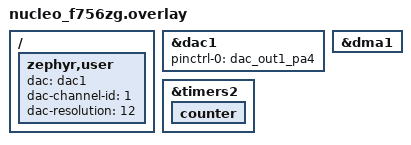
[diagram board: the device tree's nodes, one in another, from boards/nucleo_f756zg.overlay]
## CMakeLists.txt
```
# SPDX-License-Identifier: Apache-2.0

cmake_minimum_required(VERSION 3.20.0)

find_package(Zephyr REQUIRED HINTS $ENV{ZEPHYR_BASE})
project(DAC)

target_sources(app PRIVATE src/main.c)
target_sources(app PRIVATE src/dac.c)
```

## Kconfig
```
mainmenu "DAC_APP"

source "Kconfig.zephyr"
config DAC_APP_STM32
  default y
  bool
  select USE_STM32_HAL_DAC
  select USE_STM32_HAL_DAC_EX
  select USE_STM32_HAL_DMA
  select USE_STM32_HAL_CORTEX
  select USE_STM32_HAL_TIM
  select USE_STM32_HAL_TIM_EX
```

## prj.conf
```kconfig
CONFIG_DAC=y

CONFIG_SHELL=y
CONFIG_DAC_SHELL=y

CONFIG_USE_STM32_ASSERT=y

CONFIG_DMA=y
```

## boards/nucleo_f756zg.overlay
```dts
/ {
	zephyr,user {
		dac = <&dac1>;
		dac-channel-id = <1>;
		dac-resolution = <12>;
	};
};

&dac1 {
		status = "okay";
		pinctrl-0 = <&dac_out1_pa4>;
		pinctrl-names = "default";
};


//dma1: dma@40026000 {
//compatible = "st,stm32-dma-v1";
&dma1 {
		status = "okay";

};

&timers2 {
		status = "okay";
		counter {
			status = "okay";
		};

};
```

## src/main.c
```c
/*
 * Copyright (c) 2020 Libre Solar Technologies GmbH
 *
 * SPDX-License-Identifier: Apache-2.0
 */

#include <zephyr/kernel.h>
#include <zephyr/sys/printk.h>
#include <zephyr/drivers/dac.h>
#include "stm32f7xx_hal.h"
#include "stm32f7xx_ll_dac.h"
#include "stm32f7xx_hal_dac.h"
#include "dac.h"

#define ZEPHYR_USER_NODE DT_PATH(zephyr_user)

#if (DT_NODE_HAS_PROP(ZEPHYR_USER_NODE, dac) && \
	DT_NODE_HAS_PROP(ZEPHYR_USER_NODE, dac_channel_id) && \
	DT_NODE_HAS_PROP(ZEPHYR_USER_NODE, dac_resolution))
#define DAC_NODE DT_PHANDLE(ZEPHYR_USER_NODE, dac)
#define DAC_CHANNEL_ID DT_PROP(ZEPHYR_USER_NODE, dac_channel_id)
#define DAC_RESOLUTION DT_PROP(ZEPHYR_USER_NODE, dac_resolution)
#else
#error "Unsupported board: see README and check /zephyr,user node"
#define DAC_NODE DT_INVALID_NODE
#define DAC_CHANNEL_ID 0
#define DAC_RESOLUTION 0
#endif

static const struct device *const dac_dev = DEVICE_DT_GET(DAC_NODE);

static const struct dac_channel_cfg dac_ch_cfg = {
	.channel_id  = DAC_CHANNEL_ID,
	.resolution  = DAC_RESOLUTION,
	.buffered = true
};

int main(void)
{
	if (!device_is_ready(dac_dev)) {
		printk("DAC device %s is not ready\n", dac_dev->name);
		return 0;
	}

	int ret = dac_channel_setup(dac_dev, &dac_ch_cfg);

	if (ret != 0) {
		printk("Setting up of DAC channel failed with code %d\n", ret);
		return 0;
	}

	printk("Generating sawtooth signal at DAC channel %d.\n",
		DAC_CHANNEL_ID);
	//int dac_dev = 0;
	//ret = dac_write_value(dac_dev, DAC_CHANNEL_ID, 0);
	//k_timer_init(&timer2);
	//k_timer_start(&timer2, K_NO_WAIT, K_MSEC(1));
	ret = init_dac();
	ret = run_dac();
}
```

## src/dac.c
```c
#include <zephyr/kernel.h>
#include <zephyr/sys/printk.h>
//#include <zephyr/drivers/dac.h>
//#include "stm32f7xx_hal.h"
#include "stm32f7xx_ll_dac.h" // Also called in driver
#include "stm32f7xx_hal_dac.h"
#include "stm32f7xx_hal_cortex.h" // for HAL_NVIC EnableIRQ and HAL_NVIC SetPriority

DAC_HandleTypeDef hdac1;
DMA_HandleTypeDef hdma_dac1;
TIM_HandleTypeDef htim2;

void Error_Handler(void);
static void MX_DAC1_Init(void);
static void MX_DMA_Init(void);
static void MX_TIM2_Init(void);

#define NS  128

int init_dac(void)
{

	uint32_t DAC_OUT[4] = {0, 1241, 2482, 3723};
	uint32_t Wave_LUT[NS] = {
		2048, 2149, 2250, 2350, 2450, 2549, 2646, 2742, 2837, 2929, 3020, 3108, 3193, 3275, 3355,
		3431, 3504, 3574, 3639, 3701, 3759, 3812, 3861, 3906, 3946, 3982, 4013, 4039, 4060, 4076,
		4087, 4094, 4095, 4091, 4082, 4069, 4050, 4026, 3998, 3965, 3927, 3884, 3837, 3786, 3730,
		3671, 3607, 3539, 3468, 3394, 3316, 3235, 3151, 3064, 2975, 2883, 2790, 2695, 2598, 2500,
		2400, 2300, 2199, 2098, 1997, 1896, 1795, 1695, 1595, 1497, 1400, 1305, 1212, 1120, 1031,
		944, 860, 779, 701, 627, 556, 488, 424, 365, 309, 258, 211, 168, 130, 97,
		69, 45, 26, 13, 4, 0, 1, 8, 19, 35, 56, 82, 113, 149, 189,
		234, 283, 336, 394, 456, 521, 591, 664, 740, 820, 902, 987, 1075, 1166, 1258,
		1353, 1449, 1546, 1645, 1745, 1845, 1946, 2047
	};
	uint8_t i = 0;
	uint32_t err = 0;

//	HAL_Init();
//	SystemClock_Config();
//	MX_GPIO_Init();
	MX_DAC1_Init();
	MX_DMA_Init();
	MX_TIM2_Init();
//	DAC1, channel 1 (PA4) is initialized via Zephyr API
	/* Clocks, pinctrl, channel count and resolution
	 * handled by Zephyr driver in drivers/dac/dac_stm32.c
	 * */


	err = HAL_DAC_Start_DMA(&hdac1, DAC_CHANNEL_1, (uint32_t*)Wave_LUT, 128, DAC_ALIGN_12B_R);
	if (err != HAL_OK) {
		printk(err);
	 }
	HAL_TIM_Base_Start(&htim2);

	printk("IRQ 0x%x\n", arch_irq_is_enabled(16));
	printk("IRQ 0x%x\n", arch_irq_is_enabled(15));

/*	k_msleep(50);
	while (1)
	{
		DAC1->DHR12R1 = DAC_OUT[i++];
		if(i == 4)
			i = 0;
		//HAL_Delay(50); // STM32 50ms systick delay
		k_msleep(50);
	}*/
/*	while(1)
	{
		err = HAL_DAC_SetValue(&hdac1, DAC_CHANNEL_1, DAC_ALIGN_12B_R, Wave_LUT);
		k_msleep(1);
	}*/
		return 0;
}

void HAL_DAC_ConvHalfCpltCallbackCh1(DAC_HandleTypeDef *hdac)
{
	printk("Yo!");
}
void SystemClock_Config(void)
{
/*
dac1: dac@40007400 {
	compatible = "st,stm32-dac";
	reg = <0x40007400 0x400>;
	clocks = <&rcc STM32_CLOCK_BUS_APB1 0x20000000>;
	status = "disabled";
	#io-channel-cells = <1>;
};
*/
/*
rcc: rcc@40023800 {
	compatible = "st,stm32-rcc";
	#clock-cells = <2>;
	reg = <0x40023800 0x400>;
*/
}

static void MX_DAC1_Init(void)
{
	DAC_ChannelConfTypeDef sConfig = {0};

    /* Peripheral clock enable */
    __HAL_RCC_DAC_CLK_ENABLE();
/** DAC Initialization
 * Already done?
*/
	hdac1.Instance = DAC1;
	if (HAL_DAC_Init(&hdac1) != HAL_OK)
	{
	      Error_Handler();
	}
	/** DAC channel OUT1 config
	*/

	//sConfig.DAC_Trigger = DAC_TRIGGER_NONE;
	sConfig.DAC_Trigger = DAC_TRIGGER_T2_TRGO;
	sConfig.DAC_OutputBuffer = DAC_OUTPUTBUFFER_ENABLE;
	if (HAL_DAC_ConfigChannel(&hdac1, &sConfig, DAC_CHANNEL_1) != HAL_OK)
	{
	      Error_Handler();
	}
	/* Enable DMA */
	/* DAC DMA Init */
	/* DAC1 Init */
	hdma_dac1.Instance = DMA1_Stream5;
	hdma_dac1.Init.Channel = DMA_CHANNEL_7;
	hdma_dac1.Init.Direction = DMA_MEMORY_TO_PERIPH;
	hdma_dac1.Init.PeriphInc = DMA_PINC_DISABLE;
	hdma_dac1.Init.MemInc = DMA_MINC_ENABLE;
    hdma_dac1.Init.PeriphDataAlignment = DMA_PDATAALIGN_WORD;
    hdma_dac1.Init.MemDataAlignment = DMA_MDATAALIGN_HALFWORD;
    hdma_dac1.Init.Mode = DMA_CIRCULAR;
	hdma_dac1.Init.Priority = DMA_PRIORITY_HIGH;
	//hdma_dac1.Init.PeriphDataAlignment = DMA_PDATAALIGN_HALFWORD;
	//hdma_dac1.Init.MemDataAlignment = DMA_MDATAALIGN_HALFWORD;
	//hdma_dac1.Init.Mode = DMA_NORMAL;
	//hdma_dac1.Init.Priority = DMA_PRIORITY_LOW;
	hdma_dac1.Init.FIFOMode = DMA_FIFOMODE_DISABLE;
	if (HAL_DMA_Init(&hdma_dac1) != HAL_OK)
	{
	  Error_Handler();
	}
	hdac1.DMA_Handle1 = &hdma_dac1;
	hdma_dac1.Parent = &hdac1;
    	//__HAL_LINKDMA(hdac1, DMA_Handle1, hdma_dac1);
	// Manual trigger source
	//LL_DAC_SetTriggerSource(DAC1, 1, LL_DAC_TRIG_EXT_TIM2_TRGO);
}


static void MX_DMA_Init(void)
{
  // DMA1 enabled as a whole, but channel 5 no

  __HAL_RCC_DMA1_CLK_ENABLE();
  //DMA1_Stream5_IRQn
  HAL_NVIC_SetPriority(DMA1_Stream5_IRQn, 0, 0);
  HAL_NVIC_EnableIRQ(DMA1_Stream5_IRQn);

}

static void MX_GPIO_Init(void)
{
	/* GPIO Ports Clock Enable */
	//__HAL_RCC_GPIOA_CLK_ENABLE();
}

void Error_Handler(void)
{
	printk("Err\n");
}

void DMA1_Stream5_IRQHandler(void)
{
	printk("Hi!");
  	HAL_DMA_IRQHandler(&hdma_dac1);
}

void TIM2_DAC_IRQHandler(void)
{
	printk("Hi!");
  	HAL_DMA_IRQHandler(&hdma_dac1);
}

void HAL_DAC_ErrorCallbackCh1(DAC_HandleTypeDef* hdac)
{
	printk("Ouille!");
}

void HAL_DAC_DMAUnderrunCallbackCh1(DAC_HandleTypeDef* hdac)
{
	printk("Underrun");
}


static void MX_TIM2_Init(void)
{
	printk("TIM2 start\n");
	TIM_ClockConfigTypeDef sClockSourceConfig = {0};
	TIM_MasterConfigTypeDef sMasterConfig = {0};
	TIM_OC_InitTypeDef sConfigOC = {0};

	htim2.Instance = TIM2;
	htim2.Init.Prescaler = 0;
	htim2.Init.CounterMode = TIM_COUNTERMODE_UP;
	htim2.Init.Period = 1500; // 72 MHz periods / 1500 =  48kHz
	htim2.Init.ClockDivision = TIM_CLOCKDIVISION_DIV1;
	htim2.Init.AutoReloadPreload = TIM_AUTORELOAD_PRELOAD_DISABLE;
	if (HAL_TIM_PWM_Init(&htim2) != HAL_OK)
	{
	  Error_Handler();
	}
	sClockSourceConfig.ClockSource = TIM_CLOCKSOURCE_INTERNAL;
	if (HAL_TIM_ConfigClockSource(&htim2, &sClockSourceConfig) != HAL_OK)
	{
		Error_Handler();
	}
  	sMasterConfig.MasterOutputTrigger = TIM_TRGO_UPDATE;
	sMasterConfig.MasterSlaveMode = TIM_MASTERSLAVEMODE_DISABLE;
	if (HAL_TIMEx_MasterConfigSynchronization(&htim2, &sMasterConfig) != HAL_OK)
	{
	  Error_Handler();
	}
	sConfigOC.OCMode = TIM_OCMODE_PWM1;
	sConfigOC.Pulse = 0;
	sConfigOC.OCPolarity = TIM_OCPOLARITY_HIGH;
	sConfigOC.OCFastMode = TIM_OCFAST_DISABLE;
	if (HAL_TIM_PWM_ConfigChannel(&htim2, &sConfigOC, TIM_CHANNEL_2) != HAL_OK)
	{
	  Error_Handler();
	}
	// Start clock
    __HAL_RCC_TIM2_CLK_ENABLE();
}

int run_dac(void)
{
	return 0;
}
```

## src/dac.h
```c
int init_dac(void);
int run_dac(void);
```
